# GD32W515Px register map
File version: 1.0
CPU: CM33 r0p0, little endian, MPU, FPU, 4 interrupt priority bits
Registers are 32-bit, read-write, reset 0x0 unless marked. A register's access mark holds for its fields unless they carry their own. Offsets are from the block's base; [hi:lo] are bit positions; lines under a group give offsets from that group; {n}, {i} and the like mark numbered series.

## TSI — Touch sensing Interface
Base 0x40024000
Same registers: SEC_TSI 0x50024000
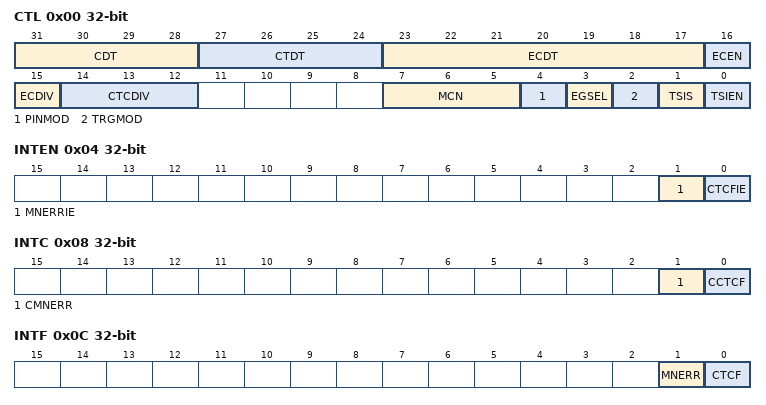
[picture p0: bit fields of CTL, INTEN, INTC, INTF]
0x00 CTL — control register
  [31:28] CDT — Charge transfer pulse high
  [27:24] CTDT — Charge transfer pulse low
  [23:17] ECDT — Spread spectrum deviation
  [16] ECEN — Spread spectrum enable
  [15] ECDIV — Spread spectrum prescaler
  [14:12] CTCDIV — pulse generator prescaler
  [7:5] MCN — Max count value
  [4] PINMOD — I/O Default mode
  [3] EGSEL — Edge selection
  [2] TRGMOD — Trigger mode selection
  [1] TSIS — Start a new acquisition
  [0] TSIEN — Touch sensing controller enable
0x04 INTEN — interrupt enable register
  [1] MNERRIE — Max Cycle Number Error Interrupt Enable
  [0] CTCFIE — Charge-transfer complete flag Interrupt Enable
0x08 INTC wo — interrupt flag clear register
  [1] CMNERR — Clear max cycle number error
  [0] CCTCF — Clear charge-transfer complete flag
0x0C INTF ro — interrupt flag register
  [1] MNERR — Max count error flag
  [0] CTCF — End of acquisition flag
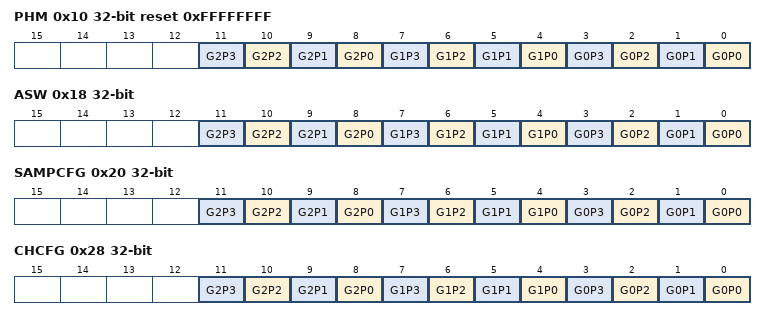
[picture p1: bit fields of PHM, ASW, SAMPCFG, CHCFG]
0x10 PHM reset 0xFFFFFFFF — Pin hysteresis mode register
  [n+8] G2P{n} (n=0..3) — G2P{n} Schmitt trigger hysteresis mode
  [n+4] G1P{n} (n=0..3) — G1P{n} Schmitt trigger hysteresis mode
  [n] G0P{n} (n=0..3) — G0P{n} Schmitt trigger hysteresis mode
0x18 ASW — I/O analog switch register
  [n+8] G2P{n} (n=0..3) — G2P{n} analog switch enable
  [n+4] G1P{n} (n=0..3) — G1P{n} analog switch enable
  [n] G0P{n} (n=0..3) — G0P{n} analog switch enable
0x20 SAMPCFG — I/O sample configuration register
  [n+8] G2P{n} (n=0..3) — G2P{n} sampling mode
  [n+4] G1P{n} (n=0..3) — G1P{n} sampling mode
  [n] G0P{n} (n=0..3) — G0P{n} sampling mode
0x28 CHCFG — I/O channel configuration register
  [n+8] G2P{n} (n=0..3) — G2P{n} channel mode
  [n+4] G1P{n} (n=0..3) — G1P{n} channel mode
  [n] G0P{n} (n=0..3) — G0P{n} channel mode
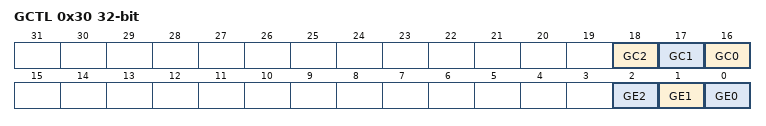
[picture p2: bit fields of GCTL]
0x30 GCTL access per field — I/O group control register
  [18] GC2 ro — Analog I/O group x status
  [17] GC1 ro — Analog I/O group x status
  [16] GC0 ro — Analog I/O group x status
  [2] GE2 rw — Analog I/O group x enable
  [1] GE1 rw — Analog I/O group x enable
  [0] GE0 rw — Analog I/O group x enable
{0x34+4i} G{i}CYCN (i=0..2) — I/O group x cycle number register
  [13:0] CYCN — Cycle number

## SPI0 — Serial peripheral interface
Base 0x40013000
Same registers: SEC_SPI0 0x50013000
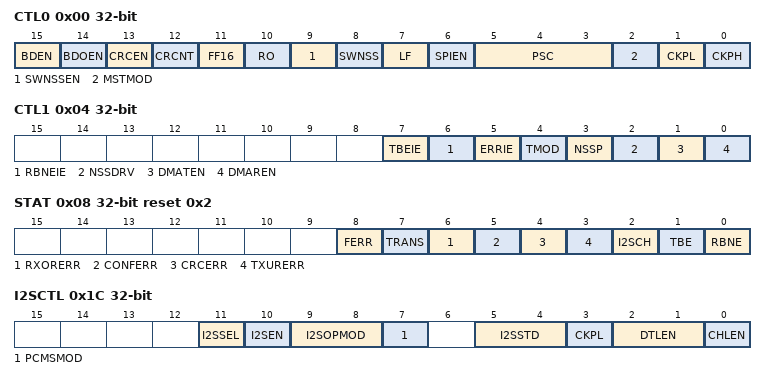
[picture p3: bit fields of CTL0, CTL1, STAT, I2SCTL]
0x00 CTL0 — control register 0
  [15] BDEN — Bidirectional enable
  [14] BDOEN — Bidirectional Transmit output enable
  [13] CRCEN — CRC Calculation Enable
  [12] CRCNT — CRC Next Transfer
  [11] FF16 — Data frame format
  [10] RO — Receive only
  [9] SWNSSEN — NSS Software Mode Selection
  [8] SWNSS — NSS Pin Selection In NSS Software Mode
  [7] LF — LSB First Mode
  [6] SPIEN — SPI enable
  [5:3] PSC — Master Clock Prescaler Selection
  [2] MSTMOD — Master Mode Enable
  [1] CKPL — Clock polarity Selection
  [0] CKPH — Clock Phase Selection
0x04 CTL1 — control register 1
  [7] TBEIE — Tx buffer empty interrupt enable
  [6] RBNEIE — RX buffer not empty interrupt enable
  [5] ERRIE — Error interrupt enable
  [4] TMOD — SPI TI Mode Enable
  [3] NSSP — SPI NSS pulse mode Enable
  [2] NSSDRV — Drive NSS Output
  [1] DMATEN — Transmit Buffer DMA Enable
  [0] DMAREN — Rx buffer DMA enable
0x08 STAT access per field reset 0x2 — status register
  [8] FERR rw — Format Error
  [7] TRANS ro — Transmitting On-going Bit
  [6] RXORERR ro — Reception Overrun Error Bit
  [5] CONFERR ro — SPI Configuration error
  [4] CRCERR rw — SPI CRC Error Bit
  [3] TXURERR ro — Transmission underrun error bit
  [2] I2SCH ro — I2S channel side
  [1] TBE ro — Transmit Buffer Empty
  [0] RBNE ro — Receive Buffer Not Empty
0x0C DATA
  [15:0] SPI_DATA — Data transfer register
0x10 CRCPOLY reset 0x7 — CRC polynomial register
  [15:0] CRCPOLY
0x14 RCRC ro — RX CRC register
  [15:0] RCRC
0x18 TCRC ro — TX CRC register
  [15:0] TCRC — Tx CRC register
0x1C I2SCTL — I2S control register
  [11] I2SSEL — I2S mode selection
  [10] I2SEN — I2S Enable
  [9:8] I2SOPMOD — I2S operation mode
  [7] PCMSMOD — PCM frame synchronization mode
  [5:4] I2SSTD — I2S standard selection
  [3] CKPL — Idle state clock polarity
  [2:1] DTLEN — Data length
  [0] CHLEN — Channel length (number of bits per audio channel)
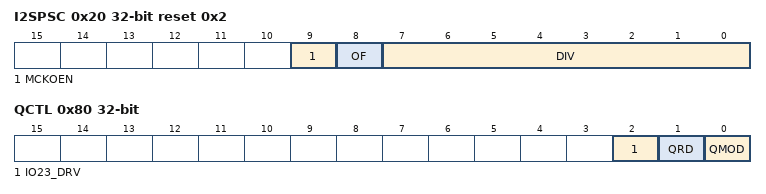
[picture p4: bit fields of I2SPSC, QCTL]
0x20 I2SPSC reset 0x2 — I2S prescaler register
  [9] MCKOEN — I2S_MCK output enable
  [8] OF — Odd factor for the prescaler
  [7:0] DIV — Dividing factor for the prescaler
0x80 QCTL — Quad-SPI mode control register
  [2] IO23_DRV — Drive IO2 and IO3 enable
  [1] QRD — Quad-SPI mode read select
  [0] QMOD — Quad-SPI mode enable

## SPI1 — Serial peripheral interface
Base 0x40003800
Same registers: I2S1_add 0x40003400, SEC_I2S1_add 0x50003400, SEC_SPI1 0x50003800
Registers as SPI0, without QCTL.
